# ESP32-S31 register map
Vendor: ESPRESSIF SYSTEMS (SHANGHAI) CO., LTD.; Series: ESP32 S-Series; File version: 1
CPU: RV32IMAFC r0p0, little endian, no MPU, FPU, 0 interrupt priority bits
Address unit: 32 bits
Registers are 32-bit, read-write, reset 0x0 unless marked. A register's access mark holds for its fields unless they carry their own. Offsets are from the block's base; [hi:lo] are bit positions; {n}, {i} and the like mark numbered series; 'fields as' and 'values as' point back to an identical list.

## AXI_PERF_MON — AXI_PERF_MON Peripheral
Base 0x20511000
0x00 CLK_EN reset 0x1 — reserved
  [0] CLK_EN
0x04 AGENT_SELECT — reserved
  [31:0] AGENT_SELECT — Select Agent in slot to be monitored, 4 bits means one agent number
{0x8+0x1C*i} SEL_AG0_COUNTER{i} ro (i=0..7) — reserved
  [31:0] RESULT — The result for sel agent metric measured in this counter, [15:0] is min result, and [31:16] is max result
{0xC+0x1C*i} SEL_AG1_COUNTER{i} ro (i=0..7) — reserved
  fields as SEL_AG0_COUNTER0
{0x10+0x1C*i} SEL_AG2_COUNTER{i} ro (i=0..7) — reserved
  fields as SEL_AG0_COUNTER0
{0x14+0x1C*i} SEL_AG3_COUNTER{i} ro (i=0..7) — reserved
  fields as SEL_AG0_COUNTER0
{0x18+0x1C*i} SEL_AG4_COUNTER{i} ro (i=0..7) — reserved
  fields as SEL_AG0_COUNTER0
{0x1C+0x1C*i} SEL_AG5_COUNTER{i} ro (i=0..7) — reserved
  fields as SEL_AG0_COUNTER0
{0x20+0x1C*i} SEL_AG6_COUNTER{i} ro (i=0..7) — reserved
  fields as SEL_AG0_COUNTER0
{0xE8+0x1C*i} SEL_AG0_RANGE{i} ro (i=0..7) — reserved
  [15:0] RESULT — The interval statistics results in this counter for sel agent
{0xEC+0x1C*i} SEL_AG1_RANGE{i} ro (i=0..7) — reserved
  fields as SEL_AG0_RANGE0
{0xF0+0x1C*i} SEL_AG2_RANGE{i} ro (i=0..7) — reserved
  fields as SEL_AG0_RANGE0
{0xF4+0x1C*i} SEL_AG3_RANGE{i} ro (i=0..7) — reserved
  fields as SEL_AG0_RANGE0
{0xF8+0x1C*i} SEL_AG4_RANGE{i} ro (i=0..7) — reserved
  fields as SEL_AG0_RANGE0
{0xFC+0x1C*i} SEL_AG5_RANGE{i} ro (i=0..7) — reserved
  fields as SEL_AG0_RANGE0
{0x100+0x1C*i} SEL_AG6_RANGE{i} ro (i=0..7) — reserved
  fields as SEL_AG0_RANGE0
{0x1C8+4i} SEL_AG{i}_RD_AXI_INFO_RECORD0 ro (i=0..6) — reserved
  [15:0] SEL_AG{i}_RD_AXI_INFO_RECORD0 — The latest x axi transaction information record for sel agent, [7:0] for ARLEN, [23:8] for ARID
{0x1E4+4i} SEL_AG{i}_RD_AXI_INFO_RECORD1 ro (i=0..6) — reserved
  [15:0] SEL_AG{i}_RD_AXI_INFO_RECORD1 — The latest x axi transaction information record for sel agent, [7:0] for ARLEN, [23:8] for ARID
{0x200+4i} SEL_AG{i}_RD_AXI_INFO_RECORD2 ro (i=0..6) — reserved
  [15:0] SEL_AG{i}_RD_AXI_INFO_RECORD2 — The latest x axi transaction information record for sel agent, [7:0] for ARLEN, [23:8] for ARID
{0x21C+4i} SEL_AG{i}_RD_AXI_INFO_RECORD3 ro (i=0..6) — reserved
  [15:0] SEL_AG{i}_RD_AXI_INFO_RECORD3 — The latest x axi transaction information record for sel agent, [7:0] for ARLEN, [23:8] for ARID
{0x238+4i} SEL_AG{i}_WR_AXI_INFO_RECORD0 ro (i=0..6) — reserved
  [15:0] SEL_AG{i}_WR_AXI_INFO_RECORD0 — The latest x axi transaction information record for sel agent, [7:0] for AWLEN, [23:8] for AWID
{0x254+4i} SEL_AG{i}_WR_AXI_INFO_RECORD1 ro (i=0..6) — reserved
  [15:0] SEL_AG{i}_WR_AXI_INFO_RECORD1 — The latest x axi transaction information record for sel agent, [7:0] for AWLEN, [23:8] for AWID
{0x270+4i} SEL_AG{i}_WR_AXI_INFO_RECORD2 ro (i=0..6) — reserved
  [15:0] SEL_AG{i}_WR_AXI_INFO_RECORD2 — The latest x axi transaction information record for sel agent, [7:0] for AWLEN, [23:8] for AWID
{0x28C+4i} SEL_AG{i}_WR_AXI_INFO_RECORD3 ro (i=0..6) — reserved
  [15:0] SEL_AG{i}_WR_AXI_INFO_RECORD3 — The latest x axi transaction information record for sel agent, [7:0] for AWLEN, [23:8] for AWID
{0x2A8+4i} SEL_AG{i}_INS_BANDW_DATA0 ro (i=0..6) — reserved
  [31:0] SEL_AG{i}_INS_BANDW_DATA0 — The latest x bandwidth date num in config time record for sel agent, [15:0] for Read and [31:16] for write
{0x2C4+4i} SEL_AG{i}_INS_BANDW_DATA1 ro (i=0..6) — reserved
  [31:0] SEL_AG{i}_INS_BANDW_DATA1 — The latest x bandwidth date num in config time record for sel agent, [15:0] for Read and [31:16] for write
{0x2E0+4i} SEL_AG{i}_INS_BANDW_DATA2 ro (i=0..6) — reserved
  [31:0] SEL_AG{i}_INS_BANDW_DATA2 — The latest x bandwidth date num in config time record for sel agent, [15:0] for Read and [31:16] for write
{0x2FC+4i} SEL_AG{i}_INS_BANDW_DATA3 ro (i=0..6) — reserved
  [31:0] SEL_AG{i}_INS_BANDW_DATA3 — The latest x bandwidth date num in config time record for sel agent, [15:0] for Read and [31:16] for write
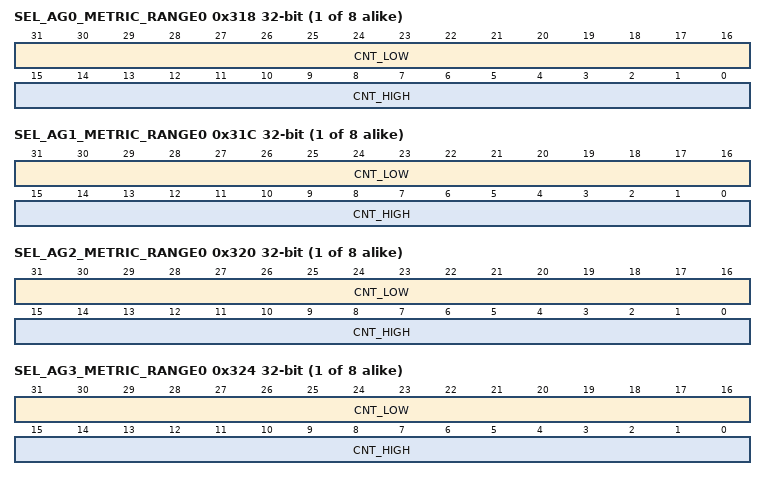
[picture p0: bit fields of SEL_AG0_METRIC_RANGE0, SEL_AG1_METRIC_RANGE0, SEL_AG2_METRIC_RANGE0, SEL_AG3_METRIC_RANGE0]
{0x318+0x1C*i} SEL_AG0_METRIC_RANGE{i} (i=0..7) — reserved
  [31:16] CNT_LOW — The x Lower limit of interval statistics for sel metric in sel agent
  [15:0] CNT_HIGH — The x Upper limit of interval statistics for sel metric in sel agent
{0x31C+0x1C*i} SEL_AG1_METRIC_RANGE{i} (i=0..7) — reserved
  fields as SEL_AG0_METRIC_RANGE0
{0x320+0x1C*i} SEL_AG2_METRIC_RANGE{i} (i=0..7) — reserved
  fields as SEL_AG0_METRIC_RANGE0
{0x324+0x1C*i} SEL_AG3_METRIC_RANGE{i} (i=0..7) — reserved
  fields as SEL_AG0_METRIC_RANGE0
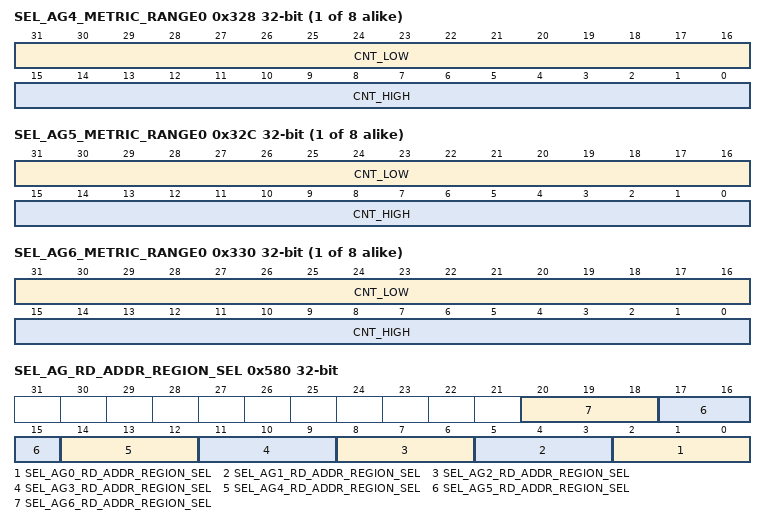
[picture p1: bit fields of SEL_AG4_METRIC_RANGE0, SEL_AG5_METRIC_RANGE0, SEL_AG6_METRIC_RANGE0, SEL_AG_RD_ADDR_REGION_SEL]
{0x328+0x1C*i} SEL_AG4_METRIC_RANGE{i} (i=0..7) — reserved
  fields as SEL_AG0_METRIC_RANGE0
{0x32C+0x1C*i} SEL_AG5_METRIC_RANGE{i} (i=0..7) — reserved
  fields as SEL_AG0_METRIC_RANGE0
{0x330+0x1C*i} SEL_AG6_METRIC_RANGE{i} (i=0..7) — reserved
  fields as SEL_AG0_METRIC_RANGE0
{0x3F8+4i} SEL_AG{i}_RD_ADDR_MASK0 (i=0..6) — reserved
  [31:0] SEL_AG{i}_RD_ADDR_MASK0 — Read addr mask of addr filter function for sel agent, mask bit will not compare with addr
{0x414+4i} SEL_AG{i}_RD_ADDR_MASK1 (i=0..6) — reserved
  [31:0] SEL_AG{i}_RD_ADDR_MASK1 — Read addr mask of addr filter function for sel agent, mask bit will not compare with addr
{0x430+4i} SEL_AG{i}_RD_ADDR_MASK2 (i=0..6) — reserved
  [31:0] SEL_AG{i}_RD_ADDR_MASK2 — Read addr mask of addr filter function for sel agent, mask bit will not compare with addr
{0x44C+4i} SEL_AG{i}_WR_ADDR_MASK0 (i=0..6) — reserved
  [31:0] SEL_AG{i}_WR_ADDR_MASK0 — Write addr mask of addr filter function for sel agent, mask bit will not compare with addr
{0x468+4i} SEL_AG{i}_WR_ADDR_MASK1 (i=0..6) — reserved
  [31:0] SEL_AG{i}_WR_ADDR_MASK1 — Write addr mask of addr filter function for sel agent, mask bit will not compare with addr
{0x484+4i} SEL_AG{i}_WR_ADDR_MASK2 (i=0..6) — reserved
  [31:0] SEL_AG{i}_WR_ADDR_MASK2 — Write addr mask of addr filter function for sel agent, mask bit will not compare with addr
{0x4A0+4i} SEL_AG{i}_RD_ADDR_FILTER0 (i=0..6) — reserved
  [31:0] SEL_AG{i}_RD_ADDR_FILTER0 — Read addr filter of addr filter function for sel agent, no mask bit in addr will compare with addr filter, if compare result same will pass filter
{0x4BC+4i} SEL_AG{i}_RD_ADDR_FILTER1 (i=0..6) — reserved
  [31:0] SEL_AG{i}_RD_ADDR_FILTER1 — Read addr filter of addr filter function for sel agent, no mask bit in addr will compare with addr filter, if compare result same will pass filter
{0x4D8+4i} SEL_AG{i}_RD_ADDR_FILTER2 (i=0..6) — reserved
  [31:0] SEL_AG{i}_RD_ADDR_FILTER2 — Read addr filter of addr filter function for sel agent, no mask bit in addr will compare with addr filter, if compare result same will pass filter
{0x4F4+4i} SEL_AG{i}_WR_ADDR_FILTER0 (i=0..6) — reserved
  [31:0] SEL_AG{i}_WR_ADDR_FILTER0 — Read addr filter of addr filter function for sel agent, no mask bit in addr will compare with addr filter, if compare result same will pass filter
{0x510+4i} SEL_AG{i}_WR_ADDR_FILTER1 (i=0..6) — reserved
  [31:0] SEL_AG{i}_WR_ADDR_FILTER1 — Read addr filter of addr filter function for sel agent, no mask bit in addr will compare with addr filter, if compare result same will pass filter
{0x52C+4i} SEL_AG{i}_WR_ADDR_FILTER2 (i=0..6) — reserved
  [31:0] SEL_AG{i}_WR_ADDR_FILTER2 — Read addr filter of addr filter function for sel agent, no mask bit in addr will compare with addr filter, if compare result same will pass filter
{0x548+4i} SEL_AG{i}_METRIC_SELECT1 (i=0..6) — reserved
  [31:0] SEL_AG{i}_METRIC_SELECT1 — Metric select Reg for sel agent, each agent use 8 bits, low 5 bits means which metric is selected for current counter, high 3 bits means range metric this counter measured, a counter can use metric and range measure at the same time
{0x564+4i} SEL_AG{i}_METRIC_SELECT2 (i=0..6) — reserved
  [31:0] SEL_AG{i}_METRIC_SELECT2 — Metric select Reg for sel agent, each agent use 8 bits, low 5 bits means which metric is selected for current counter, high 3 bits means range metric this counter measured, a counter can use metric and range measure at the same time
0x580 SEL_AG_RD_ADDR_REGION_SEL — reserved
  [3n+2:3n] SEL_AG{n}_RD_ADDR_REGION_SEL (n=0..6) — SW config Read region select, use with mask and filter, only when addr in one region and this region has been sel, will measure the transaction data num
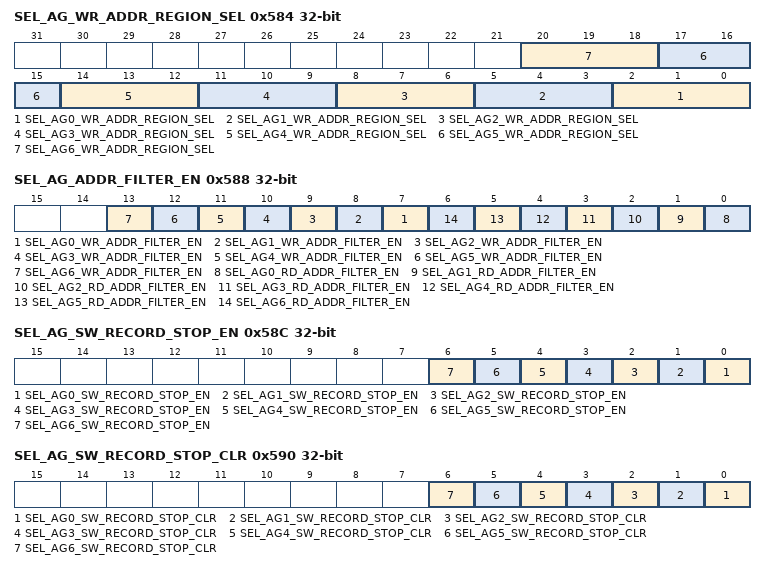
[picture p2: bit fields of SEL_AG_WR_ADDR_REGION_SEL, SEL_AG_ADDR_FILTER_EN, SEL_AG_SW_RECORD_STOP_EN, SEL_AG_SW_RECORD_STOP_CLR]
0x584 SEL_AG_WR_ADDR_REGION_SEL — reserved
  [3n+2:3n] SEL_AG{n}_WR_ADDR_REGION_SEL (n=0..6) — SW config Write region select, use with mask and filter, only when addr in one region and this region has been sel, will measure the transaction data num
0x588 SEL_AG_ADDR_FILTER_EN — reserved
  [n+7] SEL_AG{n}_WR_ADDR_FILTER_EN (n=0..6) — Enable write addr filter function, if 0, all address access will be record
  [n] SEL_AG{n}_RD_ADDR_FILTER_EN (n=0..6) — Enable read addr filter function, if 0, all address access will be record
0x58C SEL_AG_SW_RECORD_STOP_EN wo — reserved
  [n] SEL_AG{n}_SW_RECORD_STOP_EN (n=0..6) — SW use to stop event log function, record information will keep
0x590 SEL_AG_SW_RECORD_STOP_CLR wo — reserved
  [n] SEL_AG{n}_SW_RECORD_STOP_CLR (n=0..6) — SW use to clear event log function stop, record new transaction from now
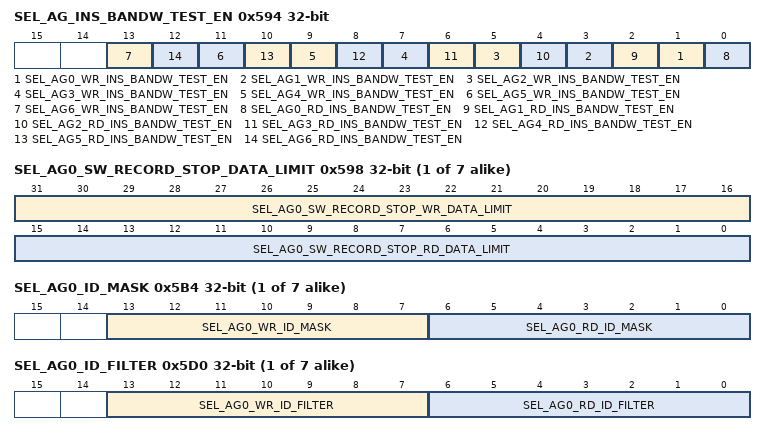
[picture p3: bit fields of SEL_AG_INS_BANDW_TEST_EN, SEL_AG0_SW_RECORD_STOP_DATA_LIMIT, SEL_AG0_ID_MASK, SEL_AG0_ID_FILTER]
0x594 SEL_AG_INS_BANDW_TEST_EN — reserved
  [2n+1] SEL_AG{n}_WR_INS_BANDW_TEST_EN (n=0..6) — Enable Read instantaneous bandwidth test for all select agent in the same time
  [2n] SEL_AG{n}_RD_INS_BANDW_TEST_EN (n=0..6) — Enable Read instantaneous bandwidth test for all select agent in the same time
{0x598+4i} SEL_AG{i}_SW_RECORD_STOP_DATA_LIMIT (i=0..6) — reserved
  [31:16] SEL_AG{i}_SW_RECORD_STOP_WR_DATA_LIMIT — Read instantaneous bandwidth test data lower limit, when touch this limit, intr enable
  [15:0] SEL_AG{i}_SW_RECORD_STOP_RD_DATA_LIMIT — Read instantaneous bandwidth test data lower limit, when touch this limit, intr enable
{0x5B4+4i} SEL_AG{i}_ID_MASK (i=0..6) — reserved
  [13:7] SEL_AG{i}_WR_ID_MASK — Write id mask, ignore mask id bits
  [6:0] SEL_AG{i}_RD_ID_MASK — Read id mask, ignore mask id bits
{0x5D0+4i} SEL_AG{i}_ID_FILTER (i=0..6) — reserved
  [13:7] SEL_AG{i}_WR_ID_FILTER — Use with mask, no mask bits must same as filter bits, the pass filter
  [6:0] SEL_AG{i}_RD_ID_FILTER — Use with mask, no mask bits must same as filter bits, the pass filter
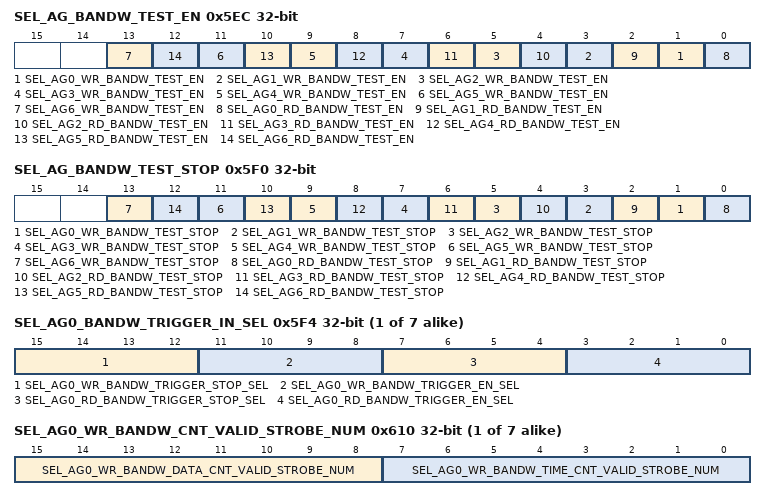
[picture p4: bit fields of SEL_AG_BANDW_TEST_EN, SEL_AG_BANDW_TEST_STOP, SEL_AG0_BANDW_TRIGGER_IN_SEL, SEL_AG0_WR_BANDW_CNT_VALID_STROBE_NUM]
0x5EC SEL_AG_BANDW_TEST_EN — reserved
  [2n+1] SEL_AG{n}_WR_BANDW_TEST_EN (n=0..6) — Enable Read average bandwidth test for all select agent in the same time
  [2n] SEL_AG{n}_RD_BANDW_TEST_EN (n=0..6) — reserved
0x5F0 SEL_AG_BANDW_TEST_STOP — reserved
  [2n+1] SEL_AG{n}_WR_BANDW_TEST_STOP (n=0..6) — Stop Read average bandwidth test for all select agent in the same time
  [2n] SEL_AG{n}_RD_BANDW_TEST_STOP (n=0..6) — reserved
{0x5F4+4i} SEL_AG{i}_BANDW_TRIGGER_IN_SEL (i=0..6) — reserved
  [15:12] SEL_AG{i}_WR_BANDW_TRIGGER_STOP_SEL — Write average bandwidth test, trigger enable by soc, sel source, SW register config is one source
  [11:8] SEL_AG{i}_WR_BANDW_TRIGGER_EN_SEL — Write average bandwidth test, trigger enable by soc, sel source, SW register config is one source
  [7:4] SEL_AG{i}_RD_BANDW_TRIGGER_STOP_SEL — Read average bandwidth test, trigger by soc, sel source, SW register config is one source
  [3:0] SEL_AG{i}_RD_BANDW_TRIGGER_EN_SEL — Read average bandwidth test, trigger enable by soc, sel source, SW register config is one source
{0x610+4i} SEL_AG{i}_WR_BANDW_CNT_VALID_STROBE_NUM (i=0..6) — reserved
  [15:8] SEL_AG{i}_WR_BANDW_DATA_CNT_VALID_STROBE_NUM — Set this register to configure the data valid scaling multiplier
  [7:0] SEL_AG{i}_WR_BANDW_TIME_CNT_VALID_STROBE_NUM — Set this register to configure the time valid scaling multiplier
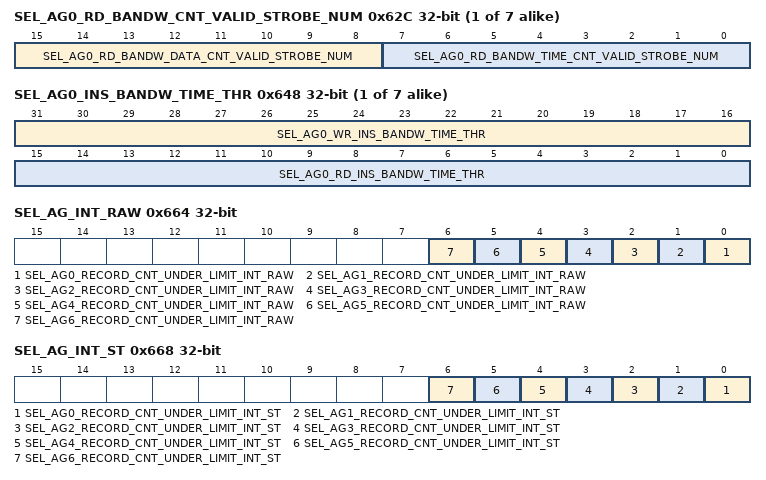
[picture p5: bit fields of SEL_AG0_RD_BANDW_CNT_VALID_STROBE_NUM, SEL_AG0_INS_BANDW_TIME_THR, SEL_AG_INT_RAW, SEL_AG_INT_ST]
{0x62C+4i} SEL_AG{i}_RD_BANDW_CNT_VALID_STROBE_NUM (i=0..6) — reserved
  [15:8] SEL_AG{i}_RD_BANDW_DATA_CNT_VALID_STROBE_NUM — Set this register to configure the data valid scaling multiplier
  [7:0] SEL_AG{i}_RD_BANDW_TIME_CNT_VALID_STROBE_NUM — Set this register to configure the time valid scaling multiplier
{0x648+4i} SEL_AG{i}_INS_BANDW_TIME_THR (i=0..6) — reserved
  [31:16] SEL_AG{i}_WR_INS_BANDW_TIME_THR — Wirte instantaneous bandwidth test time limit, counter data num in this time unit, and will fresh counter to count again
  [15:0] SEL_AG{i}_RD_INS_BANDW_TIME_THR — Read instantaneous bandwidth test time limit, counter data num in this time unit, and will fresh counter to count again
0x664 SEL_AG_INT_RAW — reserved
  [n] SEL_AG{n}_RECORD_CNT_UNDER_LIMIT_INT_RAW (n=0..6) — The raw interrupt status of instantaneous bandwidth test data under limit int
0x668 SEL_AG_INT_ST ro — reserved
  [n] SEL_AG{n}_RECORD_CNT_UNDER_LIMIT_INT_ST (n=0..6) — The masked interrupt status of instantaneous bandwidth test data under limit int
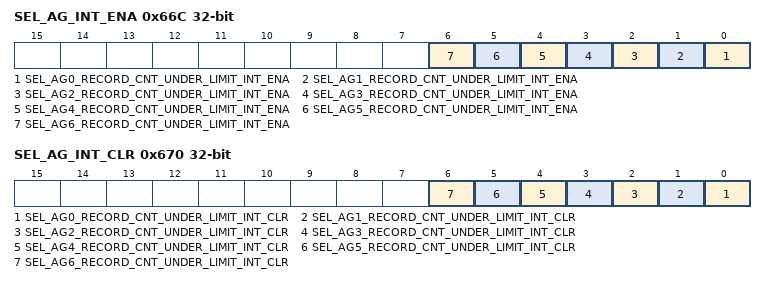
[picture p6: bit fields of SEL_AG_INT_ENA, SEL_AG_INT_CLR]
0x66C SEL_AG_INT_ENA — reserved
  [n] SEL_AG{n}_RECORD_CNT_UNDER_LIMIT_INT_ENA (n=0..6) — Write 1 to enable instantaneous bandwidth test data under limit int
0x670 SEL_AG_INT_CLR wo — reserved
  [n] SEL_AG{n}_RECORD_CNT_UNDER_LIMIT_INT_CLR (n=0..6) — Write 1 to clear instantaneous bandwidth test data under limit int
0x674 DATE reset 0x263D2E — reserved
  [27:0] DATE
